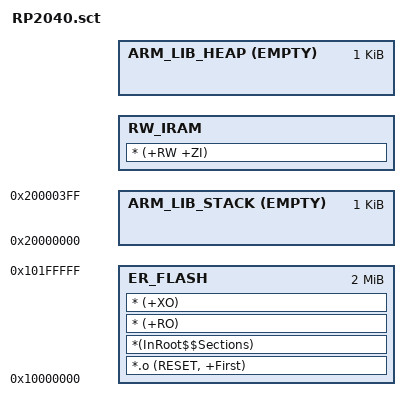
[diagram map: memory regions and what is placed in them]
; *************************************************************
; *** Scatter-Loading Description File generated by uVision ***
; *************************************************************

LR_IROM1 0x10000000 0x00200000  {    ; load region size_region
    ER_FLASH 0x10000000 0x00200000  {  ; load address = execution address
        *.o (RESET, +First)
        *(InRoot$$Sections)
        * (+RO)
        * (+XO)
    }
    
    ARM_LIB_STACK 0x20000000 ALIGN 8  EMPTY 0x00000400 {
    }
    
    RW_IRAM +0  {  ; RW data
        * (+RW +ZI)
    }
    
    ARM_LIB_HEAP  +0 ALIGN 8 EMPTY 0x00000400  {
    }
}

